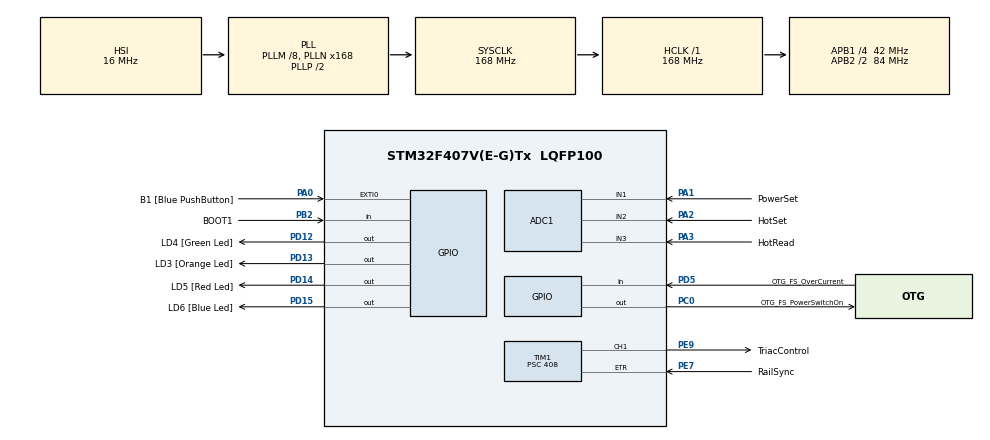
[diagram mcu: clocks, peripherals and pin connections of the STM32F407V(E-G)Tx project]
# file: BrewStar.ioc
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ADC1.Channel-0\#ChannelRegularConversion=ADC_CHANNEL_1
ADC1.Channel-1\#ChannelRegularConversion=ADC_CHANNEL_2
ADC1.Channel-3\#ChannelRegularConversion=ADC_CHANNEL_3
ADC1.ClockPrescaler=ADC_CLOCK_SYNC_PCLK_DIV8
ADC1.ContinuousConvMode=ENABLE
ADC1.DMAContinuousRequests=ENABLE
ADC1.EOCSelection=ADC_EOC_SEQ_CONV
ADC1.InjNumberOfConversion=0
ADC1.NbrOfConversion=3
ADC1.NbrOfConversionFlag=1
ADC1.Rank-0\#ChannelRegularConversion=1
ADC1.Rank-1\#ChannelRegularConversion=2
ADC1.Rank-3\#ChannelRegularConversion=3
ADC1.SamplingTime-0\#ChannelRegularConversion=ADC_SAMPLETIME_480CYCLES
ADC1.SamplingTime-1\#ChannelRegularConversion=ADC_SAMPLETIME_480CYCLES
ADC1.SamplingTime-3\#ChannelRegularConversion=ADC_SAMPLETIME_480CYCLES
ADC1.ScanConvMode=ENABLE
ADC1.master=1
Dma.ADC1.0.Direction=DMA_PERIPH_TO_MEMORY
Dma.ADC1.0.FIFOMode=DMA_FIFOMODE_DISABLE
Dma.ADC1.0.Instance=DMA2_Stream4
Dma.ADC1.0.MemDataAlignment=DMA_MDATAALIGN_HALFWORD
Dma.ADC1.0.MemInc=DMA_MINC_ENABLE
Dma.ADC1.0.Mode=DMA_CIRCULAR
Dma.ADC1.0.PeriphDataAlignment=DMA_PDATAALIGN_HALFWORD
Dma.ADC1.0.PeriphInc=DMA_PINC_DISABLE
Dma.ADC1.0.Priority=DMA_PRIORITY_MEDIUM
Dma.Request0=ADC1
Dma.Request1=TIM1_CH1
Dma.TIM1_CH1.1.Direction=DMA_MEMORY_TO_PERIPH
Dma.TIM1_CH1.1.FIFOMode=DMA_FIFOMODE_DISABLE
Dma.TIM1_CH1.1.Instance=DMA2_Stream1
Dma.TIM1_CH1.1.MemDataAlignment=DMA_MDATAALIGN_HALFWORD
Dma.TIM1_CH1.1.MemInc=DMA_MINC_DISABLE
Dma.TIM1_CH1.1.Mode=DMA_CIRCULAR
Dma.TIM1_CH1.1.PeriphDataAlignment=DMA_PDATAALIGN_HALFWORD
Dma.TIM1_CH1.1.PeriphInc=DMA_PINC_DISABLE
Dma.TIM1_CH1.1.Priority=DMA_PRIORITY_MEDIUM
Mcu.Family=STM32F4
Mcu.Name=STM32F407V(E-G)Tx
Mcu.Package=LQFP100
Mcu.UserConstants=MIN_POWER_VAL,4095;MAX_POWER_VAL,100
NVIC.DMA2_Stream1_IRQn=true\:0\:0\:false\:false\:true\:false
NVIC.DMA2_Stream4_IRQn=true\:0\:0\:false\:false\:true\:false
NVIC.EXTI0_IRQn=true\:0\:0\:false\:false\:true\:true
NVIC.PriorityGroup=NVIC_PRIORITYGROUP_0
PA0-WKUP.GPIO_Label=B1 [Blue PushButton]
PA0-WKUP.GPIO_ModeDefaultEXTI=GPIO_MODE_IT_RISING
PA0-WKUP.GPIO_PuPd=GPIO_PULLDOWN
PA0-WKUP.Signal=GPXTI0
PA1.GPIO_Label=PowerSet
PA1.Signal=ADCx_IN1
PA10.GPIO_Label=OTG_FS_ID
PA10.GPIO_Mode=GPIO_MODE_AF_PP
PA10.GPIO_PuPd=GPIO_NOPULL
PA10.GPIO_Speed=GPIO_SPEED_FREQ_LOW
PA10.Signal=USB_OTG_FS_ID
PA11.GPIO_Label=OTG_FS_DM
PA11.GPIO_Mode=GPIO_MODE_AF_PP
PA11.GPIO_PuPd=GPIO_NOPULL
PA11.GPIO_Speed=GPIO_SPEED_FREQ_LOW
PA11.Signal=USB_OTG_FS_DM
PA12.GPIO_Label=OTG_FS_DP
PA12.GPIO_Mode=GPIO_MODE_AF_PP
PA12.GPIO_PuPd=GPIO_NOPULL
PA12.GPIO_Speed=GPIO_SPEED_FREQ_LOW
PA12.Signal=USB_OTG_FS_DP
PA13.GPIO_Label=SWDIO
PA13.Mode=Serial_Wire
PA13.Signal=SYS_JTMS-SWDIO
PA14.GPIO_Label=SWCLK
PA14.Mode=Serial_Wire
PA14.Signal=SYS_JTCK-SWCLK
PA2.GPIO_Label=HotSet
PA2.Signal=ADCx_IN2
PA3.GPIO_Label=HotRead
PA3.Signal=ADCx_IN3
PA9.GPIO_Label=VBUS_FS
PA9.GPIO_Mode=GPIO_MODE_INPUT
PA9.GPIO_PuPd=GPIO_NOPULL
PA9.Signal=USB_OTG_FS_VBUS
PB2.GPIO_Label=BOOT1
PB2.GPIO_Mode=GPIO_MODE_INPUT
PB2.GPIO_PuPd=GPIO_NOPULL
PB2.Signal=GPIO_Input
PB3.GPIO_Label=SWO
PB3.Signal=SYS_JTDO-SWO
PC0.GPIO_Label=OTG_FS_PowerSwitchOn
PC0.GPIO_PuPd=GPIO_NOPULL
PC0.GPIO_Speed=GPIO_SPEED_FREQ_LOW
PC0.PinState=GPIO_PIN_SET
PC0.Signal=GPIO_Output
PC14-OSC32_IN.GPIO_Label=PC14-OSC32_IN
PC14-OSC32_IN.Signal=RCC_OSC32_IN
PC15-OSC32_OUT.GPIO_Label=PC15-OSC32_OUT
PC15-OSC32_OUT.Signal=RCC_OSC32_OUT
PD12.GPIO_Label=LD4 [Green Led]
PD12.GPIO_PuPd=GPIO_NOPULL
PD12.GPIO_Speed=GPIO_SPEED_FREQ_LOW
PD12.Signal=GPIO_Output
PD13.GPIO_Label=LD3 [Orange Led]
PD13.GPIO_PuPd=GPIO_NOPULL
PD13.GPIO_Speed=GPIO_SPEED_FREQ_LOW
PD13.Signal=GPIO_Output
PD14.GPIO_Label=LD5 [Red Led]
PD14.GPIO_PuPd=GPIO_NOPULL
PD14.GPIO_Speed=GPIO_SPEED_FREQ_LOW
PD14.Signal=GPIO_Output
PD15.GPIO_Label=LD6 [Blue Led]
PD15.GPIO_PuPd=GPIO_NOPULL
PD15.GPIO_Speed=GPIO_SPEED_FREQ_LOW
PD15.Signal=GPIO_Output
PD5.GPIO_Label=OTG_FS_OverCurrent
PD5.GPIO_Mode=GPIO_MODE_INPUT
PD5.GPIO_PuPd=GPIO_NOPULL
PD5.Signal=GPIO_Input
PE7.GPIO_Label=RailSync
PE7.GPIO_Speed=GPIO_SPEED_FREQ_HIGH
PE7.Signal=S_TIM1_ETR
PE9.GPIO_Label=TriacControl
PE9.GPIO_Speed=GPIO_SPEED_FREQ_HIGH
PE9.Signal=S_TIM1_CH1
PH0-OSC_IN.GPIO_Label=PH0-OSC_IN
PH0-OSC_IN.Signal=RCC_OSC_IN
PH1-OSC_OUT.GPIO_Label=PH1-OSC_OUT
PH1-OSC_OUT.Signal=RCC_OSC_OUT
ProjectManager.HeapSize=0x400
ProjectManager.StackSize=0x600
ProjectManager.TargetToolchain=EWARM
RCC.48MHZClocksFreq_Value=48000000
RCC.AHBFreq_Value=168000000
RCC.APB1CLKDivider=RCC_HCLK_DIV4
RCC.APB1Freq_Value=42000000
RCC.APB1TimFreq_Value=84000000
RCC.APB2CLKDivider=RCC_HCLK_DIV2
RCC.APB2Freq_Value=84000000
RCC.APB2TimFreq_Value=168000000
RCC.CortexFreq_Value=168000000
RCC.HCLKFreq_Value=168000000
RCC.HSE_VALUE=8000000
RCC.HSI_VALUE=16000000
RCC.LSE_VALUE=32768
RCC.PLLM=8
RCC.PLLN=168
RCC.PLLQ=7
RCC.SYSCLKFreq_VALUE=168000000
RCC.SYSCLKSource=RCC_SYSCLKSOURCE_PLLCLK
RCC.VCOOutputFreq_Value=336000000
SH.ADCx_IN1.0=ADC1_IN1,IN1
SH.ADCx_IN2.0=ADC1_IN2,IN2
SH.ADCx_IN3.0=ADC1_IN3,IN3
SH.S_TIM1_CH1.0=TIM1_CH1,PWM Generation1 CH1
SH.S_TIM1_ETR.0=TIM1_ETR,TriggerSource_ETR
TIM1.Channel-PWM\ Generation1\ CH1=TIM_CHANNEL_1
TIM1.CounterMode=TIM_COUNTERMODE_DOWN
TIM1.OCMode_PWM-PWM\ Generation1\ CH1=TIM_OCMODE_PWM2
TIM1.OCPolarity_1=TIM_OCPOLARITY_LOW
TIM1.Period=3000
TIM1.Prescaler=408
TIM1.Pulse-PWM\ Generation1\ CH1=50
TIM1.TIM_MasterOutputTrigger=TIM_TRGO_ENABLE
VP_TIM1_VS_ControllerModeTrigger.Mode=Trigger Mode
VP_TIM1_VS_OPM.Mode=OPM_bit
board=STM32F4DISCOVERY

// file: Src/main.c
/**
  ******************************************************************************
  * File Name          : main.c
  * Description        : Main program body
  ******************************************************************************
  ** This notice applies to any and all portions of this file
  * that are not between comment pairs USER CODE BEGIN and
  * USER CODE END. Other portions of this file, whether
  * inserted by the user or by software development tools
  * are owned by their respective copyright owners.
  *
  * COPYRIGHT(c) 2017 STMicroelectronics
  *
  * Redistribution and use in source and binary forms, with or without modification,
  * are permitted provided that the following conditions are met:
  *   1. Redistributions of source code must retain the above copyright notice,
  *      this list of conditions and the following disclaimer.
  *   2. Redistributions in binary form must reproduce the above copyright notice,
  *      this list of conditions and the following disclaimer in the documentation
  *      and/or other materials provided with the distribution.
  *   3. Neither the name of STMicroelectronics nor the names of its contributors
  *      may be used to endorse or promote products derived from this software
  *      without specific prior written permission.
  *
  * THIS SOFTWARE IS PROVIDED BY THE COPYRIGHT HOLDERS AND CONTRIBUTORS "AS IS"
  * AND ANY EXPRESS OR IMPLIED WARRANTIES, INCLUDING, BUT NOT LIMITED TO, THE
  * IMPLIED WARRANTIES OF MERCHANTABILITY AND FITNESS FOR A PARTICULAR PURPOSE ARE
  * DISCLAIMED. IN NO EVENT SHALL THE COPYRIGHT HOLDER OR CONTRIBUTORS BE LIABLE
  * FOR ANY DIRECT, INDIRECT, INCIDENTAL, SPECIAL, EXEMPLARY, OR CONSEQUENTIAL
  * DAMAGES (INCLUDING, BUT NOT LIMITED TO, PROCUREMENT OF SUBSTITUTE GOODS OR
  * SERVICES; LOSS OF USE, DATA, OR PROFITS; OR BUSINESS INTERRUPTION) HOWEVER
  * CAUSED AND ON ANY THEORY OF LIABILITY, WHETHER IN CONTRACT, STRICT LIABILITY,
  * OR TORT (INCLUDING NEGLIGENCE OR OTHERWISE) ARISING IN ANY WAY OUT OF THE USE
  * OF THIS SOFTWARE, EVEN IF ADVISED OF THE POSSIBILITY OF SUCH DAMAGE.
  *
  ******************************************************************************
  */

#include "main.h"
#include "stm32f4xx_hal.h"
#include "adc.h"
#include "dma.h"
#include "tim.h"
#include "gpio.h"

/* USER CODE BEGIN Includes */
#include "defines.h"

/* USER CODE END Includes */

/* USER CODE BEGIN PV */
/* Private variables ---------------------------------------------------------*/
uint16_t adc_read[3] = {500,0,0};

extern ADC_HandleTypeDef hadc1;
extern TIM_HandleTypeDef htim1;

/* USER CODE END PV */

void SystemClock_Config(void);

/* USER CODE BEGIN PFP */
/* Private function prototypes -----------------------------------------------*/

/* USER CODE END PFP */

int main(void)
{

  /* MCU Configuration----------------------------------------------------------*/

  /* Reset of all peripherals, Initializes the Flash interface and the Systick. */
  HAL_Init();

  /* Configure the system clock */
  SystemClock_Config();

  /* Initialize all configured peripherals */
  MX_GPIO_Init();
  MX_DMA_Init();
  MX_ADC1_Init();
  MX_TIM1_Init();

  /* USER CODE BEGIN 2 */
  BLUE_LED_DIS;
  RED_LED_EN;
  HAL_ADC_Start_DMA(&hadc1, (uint32_t *)&adc_read[0], 3);
  HAL_Delay(1000);
  /* Enable the DMA Stream */
  HAL_DMA_Start_IT(htim1.hdma[TIM_DMA_ID_CC1], (uint32_t)&adc_read[0], (uint32_t)&htim1.Instance->ARR, 1);
  /* Enable the TIM Capture/Compare 1 DMA request */
   __HAL_TIM_ENABLE_DMA(&htim1, TIM_DMA_CC1);
  HAL_TIM_PWM_Start(&htim1, TIM_CHANNEL_1);
  RED_LED_DIS;
  GREEN_LED_EN;

  /* USER CODE END 2 */

  /* Infinite loop */
  while (1)
  {

  }

}

/** System Clock Configuration
*/
void SystemClock_Config(void)
{

  RCC_OscInitTypeDef RCC_OscInitStruct;
  RCC_ClkInitTypeDef RCC_ClkInitStruct;

    /**Configure the main internal regulator output voltage
    */
  __HAL_RCC_PWR_CLK_ENABLE();

  __HAL_PWR_VOLTAGESCALING_CONFIG(PWR_REGULATOR_VOLTAGE_SCALE1);

    /**Initializes the CPU, AHB and APB busses clocks
    */
  RCC_OscInitStruct.OscillatorType = RCC_OSCILLATORTYPE_HSI;
  RCC_OscInitStruct.HSIState = RCC_HSI_ON;
  RCC_OscInitStruct.HSICalibrationValue = 16;
  RCC_OscInitStruct.PLL.PLLState = RCC_PLL_ON;
  RCC_OscInitStruct.PLL.PLLSource = RCC_PLLSOURCE_HSI;
  RCC_OscInitStruct.PLL.PLLM = 8;
  RCC_OscInitStruct.PLL.PLLN = 168;
  RCC_OscInitStruct.PLL.PLLP = RCC_PLLP_DIV2;
  RCC_OscInitStruct.PLL.PLLQ = 7;
  if (HAL_RCC_OscConfig(&RCC_OscInitStruct) != HAL_OK)
  {
    _Error_Handler(__FILE__, __LINE__);
  }

    /**Initializes the CPU, AHB and APB busses clocks
    */
  RCC_ClkInitStruct.ClockType = RCC_CLOCKTYPE_HCLK|RCC_CLOCKTYPE_SYSCLK
                              |RCC_CLOCKTYPE_PCLK1|RCC_CLOCKTYPE_PCLK2;
  RCC_ClkInitStruct.SYSCLKSource = RCC_SYSCLKSOURCE_PLLCLK;
  RCC_ClkInitStruct.AHBCLKDivider = RCC_SYSCLK_DIV1;
  RCC_ClkInitStruct.APB1CLKDivider = RCC_HCLK_DIV4;
  RCC_ClkInitStruct.APB2CLKDivider = RCC_HCLK_DIV2;

  if (HAL_RCC_ClockConfig(&RCC_ClkInitStruct, FLASH_LATENCY_5) != HAL_OK)
  {
    _Error_Handler(__FILE__, __LINE__);
  }

    /**Configure the Systick interrupt time
    */
  HAL_SYSTICK_Config(HAL_RCC_GetHCLKFreq()/1000);

    /**Configure the Systick
    */
  HAL_SYSTICK_CLKSourceConfig(SYSTICK_CLKSOURCE_HCLK);

  /* SysTick_IRQn interrupt configuration */
  HAL_NVIC_SetPriority(SysTick_IRQn, 0, 0);
}

void _Error_Handler(char * file, int line)
{
  while(1)
  {
  }
}

/************************ (C) COPYRIGHT STMicroelectronics *****END OF FILE****/
